# RockChip_RK3588 register map
Vendor: RockChip Electronics Co., Ltd.; Series: RK3588; File version: 0.1
Registers are 32-bit, read-write, no defined reset value unless marked. A register's access mark holds for its fields unless they carry their own. Offsets are from the block's base; [hi:lo] are bit positions; {n}, {i} and the like mark numbered series; 'fields as' and 'values as' point back to an identical list.

## GRF_SYS
Base 0xFD58C000
0x00 WDT_CON0 — WDT Control Register
  [0] WDTNS_PAUSE_EN — wdt pause enable. Used to freeze the watchdog counter during pause mode.
    1=ENABLE; 0=DISABLE
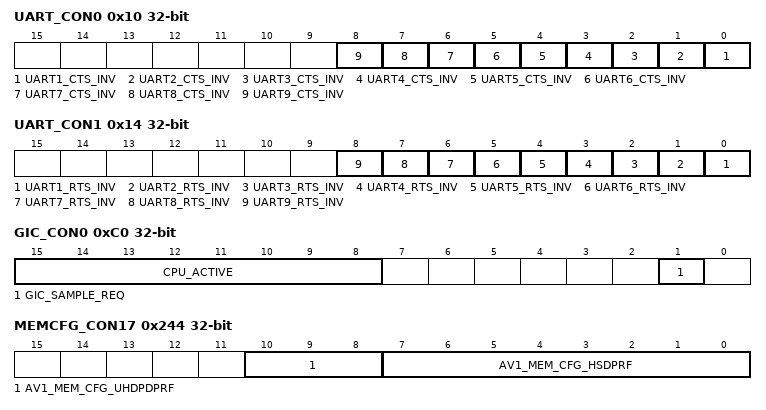
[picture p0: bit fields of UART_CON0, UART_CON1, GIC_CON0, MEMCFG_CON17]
0x10 UART_CON0 — UART Control Register 0
  [all] fields
    0=ACTIVE_LOW; 1=ACTIVE_HIGH
  [n-1] UART{n}_CTS_INV (n=1..9) — Polarity selection for uart{n}_cts.
0x14 UART_CON1 — UART Control Register 1
  [all] fields
    0=ACTIVE_LOW; 1=ACTIVE_HIGH
  [n-1] UART{n}_RTS_INV (n=1..9) — Polarity selection for uart{n}_rts.
0xC0 GIC_CON0 — GIC Control Register
  [15:8] CPU_ACTIVE — CPU active status Indicates if the core is active and not in a low-power state such as retention. The GIC can decide to target only active cores for 1 of N SPIs.
  [1] GIC_SAMPLE_REQ — GIC sample request This 4-phase handshake provides a hardware mechanism to snapshot the PMU counters and has the same effect as writing to the GICP_CAPR register.
0x200 MEMCFG_CON0 — Memory Configuration Register 0
  [15:0] RKVDEC_MEM_CFG_HDPSPRF — RKVDEC HDSPRF memory configuration bit 0: TEST1 bit 1: TEST_RNM bit 4~2: RM bit 5: WMD bit 7: LS bit 11~10: WPULSE bit 13~12: RA
0x204 MEMCFG_CON1 — Memory Configuration Register 1
  [15:0] RKVDEC_MEM_CFG_UHDPDPRF — RKVDEC UHDPDPRF memory configuration low bits bit 0: TEST1 bit 1: TEST_RNM bit 4~2: RM bit 5: WMDA bit 7: LS
0x208 MEMCFG_CON2 — Memory Configuration Register 2
  [2:0] RKVDEC_MEM_CFG_UHDPDPRF — RKVDEC UHDPDPRF memory configuration high bits bit 0: TESTRWM
0x20C MEMCFG_CON3 — Memory Configuration Register 3
  [15:0] RKVDEC_MEM_CFG_HSDPRF — RKVDEC HSDPRF memory configuration low bits bit 0: TEST1A bit 1: TEST_RNMA bit 5~2: RMA bit 6: WMDA bit 8: LS
0x210 MEMCFG_CON4 — Memory Configuration Register 4
  [7:0] RKVDEC_MEM_CFG_HSDPRF — RKVDEC HSDPRF memory configuration high bits bit 1: TEST1B bit 5~2: RMB
0x214 MEMCFG_CON5 — Memory Configuration Register 5
  [15:0] RKVENC_MEM_CFG_HDSPRF — RKVENC HDSPRF memory configuration bit 0: TEST1 bit 1: TEST_RNM bit 4~2: RM bit 5: WMD bit 7: LS bit 11~10: WPULSE bit 13~12: RA
0x218 MEMCFG_CON6 — Memory Configuration Register 6
  [15:0] RKVENC_MEM_CFG_UHDPDPRF — RKVENC UHDPDPRF memory configuration low bits bit 0: TEST1 bit 1: TEST_RNM bit 4~2: RM bit 5: WMDA bit 7: LS
0x21C MEMCFG_CON7 — Memory Configuration Register 7
  [2:0] RKVENC_MEM_CFG_UHDPDPRF — RKVENC UHDPDPRF memory configuration high bits bit 0: TESTRWM
0x220 MEMCFG_CON8 — Memory Configuration Register 8
  [15:0] RKVENC_MEM_CFG_HSDPRF — RKVENC HSDPRF memory configuration low bits bit 0: TEST1A bit 1: TEST_RNMA bit 5~2: RMA bit 6: WMDA bit 8: LS
0x224 MEMCFG_CON9 — Memory Configuration Register 9
  [7:0] RKVENC_MEM_CFG_HSDPRF — RKVENC HSDPRF memory configuration high bits bit 1: TEST1B bit 5~2: RMB
0x228 MEMCFG_CON10 — Memory Configuration Register 10
  [15:0] VDPU_MEM_CFG_HDSPRF — VDPU HDSPRF memory configuration bit 0: TEST1 bit 1: TEST_RNM bit 4~2: RM bit 5: WMD bit 7: LS bit 11~10: WPULSE bit 13~12: RA
0x22C MEMCFG_CON11 — Memory Configuration Register 11
  [15:0] VDPU_MEM_CFG_UHDPDPRF — VDPU UHDPDPRF memory configuration low bits bit 0: TEST1 bit 1: TEST_RNM bit 4~2: RM bit 5: WMDA bit 7: LS
0x230 MEMCFG_CON12 — Memory Configuration Register 12
  [2:0] VDPU_MEM_CFG_UHDPDPRF — VDPU UHDPDPRF memory configuration high bits bit 0: TESTRWM
0x234 MEMCFG_CON13 — Memory Configuration Register 13
  [15:0] VDPU_MEM_CFG_HSDPRF — VDPU HSDPRF memory configuration low bits bit 0: TEST1A bit 1: TEST_RNMA bit 5~2: RMA bit 6: WMDA bit 8: LS
0x238 MEMCFG_CON14 — Memory Configuration Register 14
  [7:0] VDPU_MEM_CFG_HSDPRF — VDPU HSDPRF memory configuration high bits bit 1: TEST1B bit 5~2: RMB
0x23C MEMCFG_CON15 — Memory Configuration Register 15
  [7:0] VDPU_MEM_CFG_ROM — VDPU ROM memory configuration bit 0: TEST1 bit 4~1: RM bit 5: LS
0x240 MEMCFG_CON16 — Memory Configuration Register 16
  [15:0] AV1_MEM_CFG_HSDPRF — AV1 HSDPRF memory configuration low bits bit 0: TEST1A bit 1: TEST_RNMA bit 5~2: RMA bit 6: WMDA bit 8: LS
0x244 MEMCFG_CON17 — Memory Configuration Register 17
  [10:8] AV1_MEM_CFG_UHDPDPRF — AV1 UHDPDPRF memory configuration high bits bit 8: TESTRWM
  [7:0] AV1_MEM_CFG_HSDPRF — AV1 HSDPRF memory configuration high bits bit 1: TEST1B bit 5~2: RMB
0x248 MEMCFG_CON18 — Memory Configuration Register 18
  [15:0] AV1_MEM_CFG_UHDPDPRF — AV1 UHDPDPRF memory configuration low bits bit 0: TEST1 bit 1: TEST_RNM bit 4~2: RM bit 5: WMDA bit 7: LS
0x24C MEMCFG_CON19 — Memory Configuration Register 19
  [15:0] AV1_MEM_CFG_HDSPRF — AV1 HDSPRF memory configuration bit 0: TEST1 bit 1: TEST_RNM bit 4~2: RM bit 5: WMD bit 7: LS bit 11~10: WPULSE bit 13~12: RA
0x250 MEMCFG_CON20 — Memory Configuration Register 20
  [7:0] SYS_MEM_CFG_ROM — ROM memory configuration bit 0: TEST1 bit 4~1: RM bit 5: LS
0x254 MEMCFG_CON21 — Memory Configuration Register 21
  [15:0] SYS_MEM_CFG_HDSPRF — system HDSPRF memory configuration bit 0: TEST1 bit 1: TEST_RNM bit 4~2: RM bit 5: WMD bit 7: LS bit 11~10: WPULSE bit 13~12: RA
0x258 MEMCFG_CON22 — Memory Configuration Register 22
  [15:0] SYS_MEM_CFG_HSDPRF — system HSDPRF memory configuration low bits bit 0: TEST1A bit 1: TEST_RNMA bit 5~2: RMA bit 6: WMDA bit 8: LS
0x25C MEMCFG_CON23 — Memory Configuration Register 23
  [7:0] SYS_MEM_CFG_HSDPRF — system HSDPRF memory configuration high bits bit 1: TEST1B bit 5~2: RMB
0x260 MEMCFG_CON24 — Memory Configuration Register 24
  [15:0] SYS_MEM_CFG_HSSPRA — system HSSPRA memory configuration bit 0: TEST1 bit 1: TEST_RNM bit 4~2: RM bit 5: WMD bit 7: LS
0x268 MEMCFG_CON26 — Memory Configuration Register 26
  [15:0] SYS_MEM_CFG_HSDPRA — system HSDPRA memory configuration low bits bit 0: TEST1A bit 1: TEST_RNMA bit 4~2: RMA bit 5: WMDA bit 7: LS bit 11~10: WPULSE bit 13~12: RA bit 15~14: WA
0x26C MEMCFG_CON27 — Memory Configuration Register 27
  [8:0] SYS_MEM_CFG_HSDPRA — system HSDPRA memory configuration high bits bit 0: TEST1B bit 1: TEST_RNMB bit 4~2: RMB bit 5: WMDB
0x270 MEMCFG_CON28 — Memory Configuration Register 28
  [15:0] VI_MEM_CFG_HDSPRF — VI subsystem HDSPRF memory configuration bit 0: TEST1 bit 1: TEST_RNM bit 4~2: RM bit 5: WMD bit 7: LS bit 11~10: WPULSE bit 13~12: RA
0x274 MEMCFG_CON29 — Memory Configuration Register 29
  [15:0] VI_MEM_CFG_HSDPRF — VI subsystem HSDPRF memory configuration low bits bit 0: TEST1A bit 1: TEST_RNMA bit 5~2: RMA bit 6: WMDA bit 8: LS
0x278 MEMCFG_CON30 — Memory Configuration Register 30
  [7:0] VI_MEM_CFG_HSDPRF — VI subsystem HSDPRF memory configuration high bits bit 1: TEST1B bit 5~2: RMB
0x27C MEMCFG_CON31 — Memory Configuration Register 31
  [15:0] VI_MEM_CFG_HSSPRA — VI subsystem HSSPRA memory configuration bit 0: TEST1 bit 1: TEST_RNM bit 4~2: RM bit 5: WMD bit 7: LS
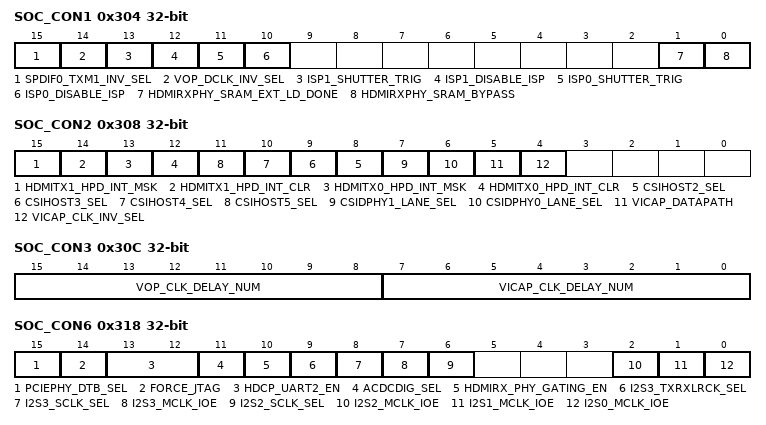
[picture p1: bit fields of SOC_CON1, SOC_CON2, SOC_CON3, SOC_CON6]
0x304 SOC_CON1 — System Control Register 1
  [15] SPDIF0_TXM1_INV_SEL — Select SPDIF0_TXM1 to IO invert or not
    0=NORMAL; 1=INVERT
  [14] VOP_DCLK_INV_SEL
    0=NORMAL; 1=INVERT
  [13] ISP1_SHUTTER_TRIG — ISP1 shutter trigger. High valid.
  [12] ISP1_DISABLE_ISP — disable ISP1 function. High valid.
  [11] ISP0_SHUTTER_TRIG — ISP0 shutter trigger. High valid.
  [10] ISP0_DISABLE_ISP — disable ISP0 function. High valid.
  [1] HDMIRXPHY_SRAM_EXT_LD_DONE — HDMIRX PHY SRAM external load done This signal asserted by user after any updates to the SRAM have been loaded.
  [0] HDMIRXPHY_SRAM_BYPASS — HDMI RXPHY SRAM bypass control when sram bypass control signal asserted, bypasses the SRAM interface. In this case, the adaptation and calibration algorithms are executed from the hard wired values within the Raw PCS. If SRAM is not bypassed, the internal algorithms are first loaded by Raw PCS into the SRAM at which point user can change the contents of the SRAM. The updated SRAM contents are used for the adaptation and calibration routines. This signal is meant to be used only for debugging purposes and must not change after phy_reset is negated.
0x308 SOC_CON2 — System Control Register 2
  [15] HDMITX1_HPD_INT_MSK — HDMI TX1 HPD interrupt mask
    0=ENABLE (Interrupt enable); 1=DISABLE (Interrupt disable)
  [14] HDMITX1_HPD_INT_CLR — A posedge of hdmitx1_hpd_int_clr will clear the HDMI TX1 HPD interrupt.
  [13] HDMITX0_HPD_INT_MSK — HDMI TX0 HPD interrupt mask
    0=ENABLE (Interrupt enable); 1=DISABLE (Interrupt disable)
  [12] HDMITX0_HPD_INT_CLR — A posedge of hdmitx0_hpd_int_clr will clear the HDMI TX0 HPD interrupt.
  [n+6] CSIHOST{n}_SEL (n=2..5) — CSIHOST{n} mode select. This bit is valid only in D-PHY split mode.
    0=D_PHY_LANE_01 (Connect to D-PHY lane 0/1); 1=D_PHY_LANE_23 (Connect to D-PHY lane 2/3)
  [7] CSIDPHY1_LANE_SEL — CSIDPHY 1 pipe clock select. If CSIDPHY works as full mode, set this bit to 0. If CSIDPHY works as split mode, set this bit to 1.
    0=CLOCK_LANE_0 (Select clock lane 0 to pipe CSIDPHY data[31:16]); 1=CLOCK_LANE_1 (Select clock lane 1 to pipe CSIDPHY data[31:16])
  [6] CSIDPHY0_LANE_SEL — CSIDPHY 0 pipe clock select. If CSIDPHY works as full mode, set this bit to 0, If CSIDPHY works as split mode, set this bit to 1.
    values as CSIDPHY1_LANE_SEL
  [5] VICAP_DATAPATH
    0=SINGLE_EDGE_MODE (Select single edge mode); 1=DUAL_EDGE_MODE (Select dual edge mode)
  [4] VICAP_CLK_INV_SEL — VICAP clock invert select
    0=NORMAL (Do not invert VICAP clock in); 1=INVERT (Invert VICAP clock in)
0x30C SOC_CON3 — System Control Register 3
  [15:8] VOP_CLK_DELAY_NUM — VOP clock delayline length control
  [7:0] VICAP_CLK_DELAY_NUM — VIP clock delayline length control
0x318 SOC_CON6 — System Control Register 6
  [15] PCIEPHY_DTB_SEL — PCIEPHY DTB select
    0=PCIE0 (Select PCIE0 PHY DTB output to IO); 1=PCIE1 (Select PCIE1 PHY DTB output to IO)
  [14] FORCE_JTAG — Force SDMMC IO to JTAG function enable When force_jtag is high , gpio4_d2_sel is 0x1 , gpio4_d3_sel is 0x1, and SDMMC_DETECTN is inactive, switch the SDMMC IO to CPU JTAG function.
  [13:12] HDCP_UART2_EN — HDCP uart enable
    1=HDCP0 (UART2 IO is used for HDCP 0); 2=HDCP1 (UART2 IO is used for HDCP 1)
  [11] ACDCDIG_SEL — ACDC path select
    0=IO (I2S3 connect to IO); 1=DSM_PWM (I2S3 connect to DSM_PWM)
  [10] HDMIRX_PHY_GATING_EN — HDMI RXPHY memory clock gating enable
    0=DISABLE (HDMIRX PHY memory clock auto gating disable); 1=ENABLE (HDMIRX PHY memory clock auto gating enable)
  [9] I2S3_TXRXLRCK_SEL — I2S3 lrck select
    0=RX (Select i2s3_rx_lrck as lrck); 1=TX (Select i2s3_tx_lrck as lrck)
  [8] I2S3_SCLK_SEL — I2S3 sclk select
    0=RX (Select i2s3_sclk_in_rx as sclk); 1=TX (Select i2s3_sclk_in_tx as sclk)
  [7] I2S3_MCLK_IOE — I2S3_MCLK output enable
    0=ENABLE (Output enable); 1=DISABLE (Output disable)
  [6] I2S2_SCLK_SEL — I2S2 sclk select
    0=RX (Select i2s2_sclk_in_rx as sclk); 1=TX (Select i2s2_sclk_in_tx as sclk)
  [2] I2S2_MCLK_IOE — I2S2_MCLK output enable
    0=ENABLE (Output enable); 1=DISABLE (Output disable)
  [1] I2S1_MCLK_IOE — I2S1_MCLK output enable
    0=ENABLE (Output enable); 1=DISABLE (Output disable)
  [0] I2S0_MCLK_IOE — I2S0_MCLK output enable
    0=ENABLE (Output enable); 1=DISABLE (Output disable)
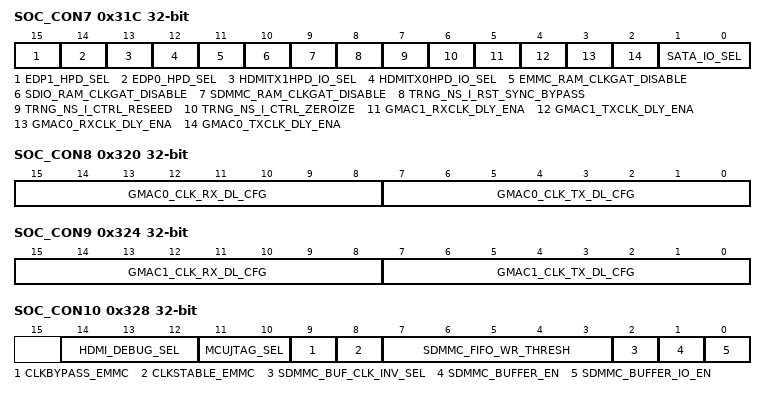
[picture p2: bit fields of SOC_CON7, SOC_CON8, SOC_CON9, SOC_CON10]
0x31C SOC_CON7 — System Control Register 7
  [15] EDP1_HPD_SEL
    0=TIE_1 (Tie EDP1 hpd to 1); 1=TIE_IO (Connect EDP1 hpd to IO)
  [14] EDP0_HPD_SEL
    0=TIE_1 (Tie EDP0 hpd to 1); 1=TIE_IO (Connect EDP0 hpd to IO)
  [13] HDMITX1HPD_IO_SEL
    0=TIE_0 (Tie HDMITX1 hpd to 0); 1=TIE_IO (Connect HDMITX1 hpd to IO)
  [12] HDMITX0HPD_IO_SEL
    0=TIE_0 (Tie HDMITX0 hpd to 0); 1=TIE_IO (Connect HDMITX0 hpd to IO)
  [11] EMMC_RAM_CLKGAT_DISABLE
    0=GATE (Gate EMMC memory clock when idle); 1=ALWAYS_ON (EMMC memory clock is always on)
  [10] SDIO_RAM_CLKGAT_DISABLE
    0=GATE (Gate SDIO memory clock when idle); 1=ALWAYS_ON (SDIO memory clock is always on)
  [9] SDMMC_RAM_CLKGAT_DISABLE
    0=GATE (Gate SDMMC memory clock when idle); 1=ALWAYS_ON (SDMMC memory clock is always on)
  [8] TRNG_NS_I_RST_SYNC_BYPASS — when high, bypass the reset synchronization logic.
  [7] TRNG_NS_I_CTRL_RESEED — control the non-secure TRNG to regenerate the random seed.
  [6] TRNG_NS_I_CTRL_ZEROIZE — used to clear the state and seed of non-secure TRNG.
  [5] GMAC1_RXCLK_DLY_ENA — RGMII RX clock delayline enable
    0=DISABLE; 1=ENABLE
  [4] GMAC1_TXCLK_DLY_ENA — RGMII TX clock delayline enable
    0=DISABLE; 1=ENABLE
  [3] GMAC0_RXCLK_DLY_ENA — RGMII RX clock delayline enable
    0=DISABLE; 1=ENABLE
  [2] GMAC0_TXCLK_DLY_ENA — RGMII TX clock delayline enable
    0=DISABLE; 1=ENABLE
  [1:0] SATA_IO_SEL — SATA IO select
    0=SATA0 (Select SATA0 cp_det / mp_switch / cp_pod to IO); 1=SATA1 (Select SATA1 cp_det / mp_switch / cp_pod to IO); 2=SATA2 (Select SATA2 cp_det / mp_switch / cp_pod to IO)
0x320 SOC_CON8 — System Control Register 8
  [15:8] GMAC0_CLK_RX_DL_CFG — GMAC0 RX clock delayline configuration MAC recept clock delay length configuration
  [7:0] GMAC0_CLK_TX_DL_CFG — GMAC0 TX clock delayline configuration MAC transmit clock delay length configuration
0x324 SOC_CON9 — System Control Register 9
  [15:8] GMAC1_CLK_RX_DL_CFG — GMAC1 RX clock delayline configuration MAC recept clock delay length configuration
  [7:0] GMAC1_CLK_TX_DL_CFG — GMAC1 TX clock delayline configuration MAC transmit clock delay length configuration
0x328 SOC_CON10 — System Control Register 10
  [14:12] HDMI_DEBUG_SEL — HDMI DEBUG IO select select different debug signals to IO.
  [11:10] MCUJTAG_SEL
    0=PMU_MCU (JTAG IO select PMU MCU); 1=DDR_MCU (JTAG IO select DDR MCU); 2=GPU_MCU (JTAG IO select GPU MCU); 3=NPU_MCU (JTAG IO select NPU MCU)
  [9] CLKBYPASS_EMMC — clock gate bypass
    0=ENABLE (Enable clock gate of EMMC); 1=DISABLE (Disable clock gate of EMMC)
  [8] CLKSTABLE_EMMC — card clock stable When asserted it indicates that the card clock is stable. Active State: High
    1=STABLE
  [7:3] SDMMC_FIFO_WR_THRESH — SDMMC BUFFER FIFO threshold control When the space of SDMMC BUFFER FIFO is more than the threshold, SDMMC BUFFER module will send the dma request signal.
  [2] SDMMC_BUF_CLK_INV_SEL — SDMMC BUFFER clock invert select
    0=NORMAL (Do not invert SDMMC BUFFER clock output); 1=INVERT (Invert SDMMC BUFFER clock output)
  [1] SDMMC_BUFFER_EN — SDMMC BUFFER enable
    0=DISABLE (SDMMC BUFFER module disable); 1=ENABLE (SDMMC BUFFER module enable)
  [0] SDMMC_BUFFER_IO_EN — SDMMC BUFFER IO select
    0=SDMMC (Select SDMMC to SDMMC IO); 1=SDMMC_BUFFER (Select SDMMC BUFFER to SDMMC IO)
0x32C SOC_CON11 — System Control Register 11
  [31:0] SDCARD_DECTN_DLY — Delay counter setting after sdcard plug out. Counted by 24M clock
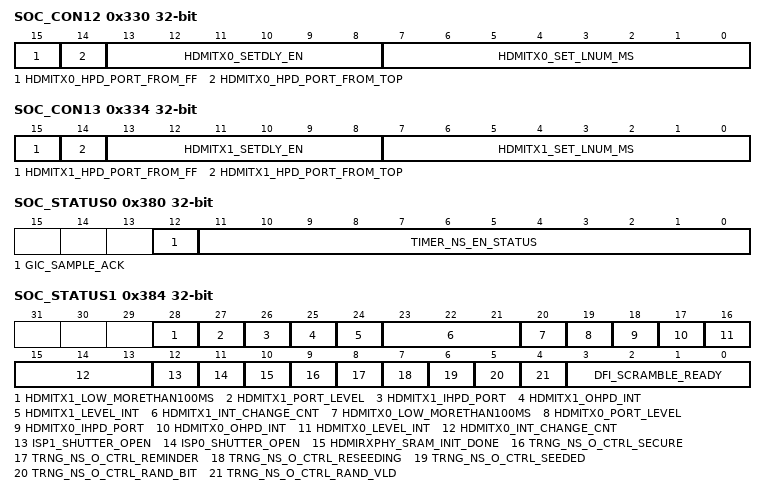
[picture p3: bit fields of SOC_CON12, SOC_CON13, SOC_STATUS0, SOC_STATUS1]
0x330 SOC_CON12 — System Control Register 12
  [15] HDMITX0_HPD_PORT_FROM_FF
    1=ACTIVE (Active the register as the input hpd port); 0=INACTIVE (Inactive the register as the input hpd port)
  [14] HDMITX0_HPD_PORT_FROM_TOP
    1=ACTIVE (Active the top level's hpd port as the input hpd port); 0=INACTIVE (Inactive the top level's hpd port as the input hpd port)
  [13:8] HDMITX0_SETDLY_EN
    0=Inactive SET_LNUM_MS value
  [7:0] HDMITX0_SET_LNUM_MS — The low level count threshold value. For example: 20 means low level stable 20ms.
0x334 SOC_CON13 — System Control Register 13
  [15] HDMITX1_HPD_PORT_FROM_FF
    values as SOC_CON12.HDMITX0_HPD_PORT_FROM_FF
  [14] HDMITX1_HPD_PORT_FROM_TOP
    values as SOC_CON12.HDMITX0_HPD_PORT_FROM_TOP
  [13:8] HDMITX1_SETDLY_EN
    0=INACTIVE (Inactive SET_LNUM_MS value Others not)
  [7:0] HDMITX1_SET_LNUM_MS — The low level count threshold value. For example: 20 means low level stable 20ms.
0x380 SOC_STATUS0 — System Status Register 0
  [12] GIC_SAMPLE_ACK ro — Used with gic_sample_req. This 4-phase handshake provides a mechanism to snapshot the PMU counters and has the same effects as writting to the GICP_CAPR register.
  [11:0] TIMER_NS_EN_STATUS ro — TIMER_NS enable status
0x384 SOC_STATUS1 — System Status Register 1
  [28] HDMITX1_LOW_MORETHAN100MS ro
    0=LOW_LEVEL (Low more than 100 ms (Internal signal of the HPD module) signal is low level); 1=HIGH_LEVEL (Low more than 100 ms (Internal signal of the HPD module) signal is high level)
  [27] HDMITX1_PORT_LEVEL ro
    0=LOW_LEVEL (HPD_PORT_LEVEL (Internal signal of the HPD module) signal is low level); 1=HIGH_LEVEL (HPD_PORT_LEVEL (Internal signal of the HPD module) signal is high level)
  [26] HDMITX1_IHPD_PORT ro
    0=LOW_LEVEL (IHPD_PORT (Input signal of the HPD module) signal is low level); 1=HIGH_LEVEL (IHPD_PORT (Input signal of the HPD module) signal is high level)
  [25] HDMITX1_OHPD_INT ro
    0=LOW_LEVEL (Ohpd_int (Output signal of the HPD module) signal is low level); 1=HIGH_LEVEL (Ohpd_int (Output signal of the HPD module) signal is high level)
  [24] HDMITX1_LEVEL_INT ro
    0=LOW_LEVEL (Level Interrupt signal is low level); 1=HIGH_LEVEL (Level Interrupt signal is high level)
  [23:21] HDMITX1_INT_CHANGE_CNT ro — Store the interrupt change times.
  [20] HDMITX0_LOW_MORETHAN100MS ro
    values as HDMITX1_LOW_MORETHAN100MS
  [19] HDMITX0_PORT_LEVEL ro
    values as HDMITX1_PORT_LEVEL
  [18] HDMITX0_IHPD_PORT ro
    values as HDMITX1_IHPD_PORT
  [17] HDMITX0_OHPD_INT ro
    values as HDMITX1_OHPD_INT
  [16] HDMITX0_LEVEL_INT ro
    values as HDMITX1_LEVEL_INT
  [15:13] HDMITX0_INT_CHANGE_CNT ro — Store the interrupt change times.
  [12] ISP1_SHUTTER_OPEN ro — ISP1 shutter open High valid.
    1=VALID
  [11] ISP0_SHUTTER_OPEN ro — ISP0 shutter open High valid
    1=VALID
  [10] HDMIRXPHY_SRAM_INIT_DONE ro — HDMIRX PHY SRAM initialization done status The bit indicates that the SRAM has been initialized by the boot loader in the Raw PCS.
  [9] TRNG_NS_O_CTRL_SECURE ro — Non-Secure TRNG status Secure mode output, high valid.
    1=VALID
  [8] TRNG_NS_O_CTRL_REMINDER ro — Non-Secure TRNG status Reseed reminder output, high pulse valid.
    1=VALID
  [7] TRNG_NS_O_CTRL_RESEEDING ro — Non-Secure TRNG status Reseeding activity output, high valid.
    1=VALID
  [6] TRNG_NS_O_CTRL_SEEDED ro — Non-Secure TRNG status (Re)Seeding completion output, high valid.
    1=VALID
  [5] TRNG_NS_O_CTRL_RAND_BIT ro — Non-Secure TRNG status Serial random bit output.
  [4] TRNG_NS_O_CTRL_RAND_VLD ro — Non-Secure TRNG status Serial random bit valid output, high valid.
    1=VALID
  [3:0] DFI_SCRAMBLE_READY ro — DFI scramble key is ready, high valid.
    1=VALID
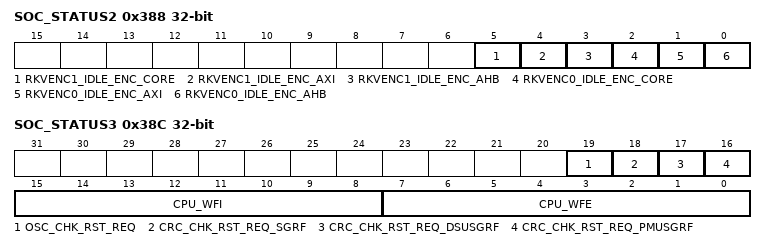
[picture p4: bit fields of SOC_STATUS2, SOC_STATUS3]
0x388 SOC_STATUS2 — System Status Register 2
  [5] RKVENC1_IDLE_ENC_CORE ro — RKVENC1 idle status
  [4] RKVENC1_IDLE_ENC_AXI ro — RKVENC1 idle status
  [3] RKVENC1_IDLE_ENC_AHB ro — RKVENC1 idle status
  [2] RKVENC0_IDLE_ENC_CORE ro — RKVENC0 idle status
  [1] RKVENC0_IDLE_ENC_AXI ro — RKVENC0 idle status
  [0] RKVENC0_IDLE_ENC_AHB ro — RKVENC0 idle status
0x38C SOC_STATUS3 — System Status Register 3
  [19] OSC_CHK_RST_REQ ro — OSC frequency check error
  [18] CRC_CHK_RST_REQ_SGRF ro — SGRF in pd_bus crc check error
  [17] CRC_CHK_RST_REQ_DSUSGRF ro — SGRF in pd_core crc check error
  [16] CRC_CHK_RST_REQ_PMUSGRF ro — SGRF in pd_pmu crc check error
  [15:8] CPU_WFI ro — CPU WFI status
  [7:0] CPU_WFE ro — CPU WFE status
0x500 OTP_KEY08 — OTP Status Register 8
  [0] KEY08 — The value of OTP address 0x8
0x504 OTP_KEY0D — OTP Status Register 13
  [0] KEY0D — The value of OTP address 0xd
0x508 OTP_KEY0E — OTP Status Register 14
  [0] KEY0E — The value of OTP address 0xe
0x600 CHIP_ID
